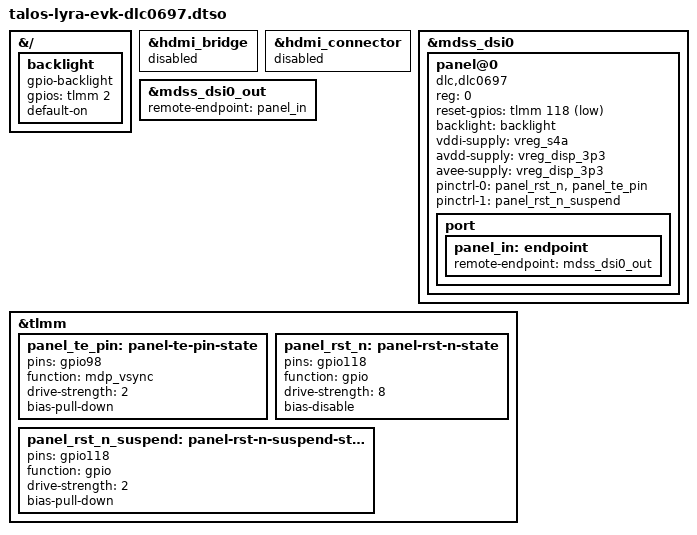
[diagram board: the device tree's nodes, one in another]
// SPDX-License-Identifier: BSD-3-Clause
/*
 * Copyright (c) Qualcomm Technologies, Inc. and/or its subsidiaries.
 */
/dts-v1/;
/plugin/;

#include <dt-bindings/gpio/gpio.h>

&{/} {
	backlight: backlight {
		compatible = "gpio-backlight";
		gpios = <&tlmm 2 GPIO_ACTIVE_HIGH>;
		default-on;
	};
};

&hdmi_bridge {
	status = "disabled";
};

&hdmi_connector {
	status = "disabled";
};

&mdss_dsi0 {
	#address-cells = <1>;
	#size-cells = <0>;

	panel@0 {
		compatible = "dlc,dlc0697", "ilitek,ili7807s";
		reg = <0>;

		reset-gpios = <&tlmm 118 GPIO_ACTIVE_LOW>;
		backlight = <&backlight>;

		vddi-supply = <&vreg_s4a>;
		avdd-supply = <&vreg_disp_3p3>;
		avee-supply = <&vreg_disp_3p3>;

		pinctrl-0 = <&panel_rst_n &panel_te_pin>;
		pinctrl-1 = <&panel_rst_n_suspend>;
		pinctrl-names = "default", "sleep";

		port {
			panel_in: endpoint {
				remote-endpoint = <&mdss_dsi0_out>;
			};
		};
	};
};

&mdss_dsi0_out {
	remote-endpoint = <&panel_in>;
};

&tlmm {
	panel_te_pin: panel-te-pin-state {
		pins = "gpio98";
		function = "mdp_vsync";
		drive-strength = <2>;
		bias-pull-down;
	};

	panel_rst_n: panel-rst-n-state {
		pins = "gpio118";
		function = "gpio";
		drive-strength = <8>;
		bias-disable;
	};

	panel_rst_n_suspend: panel-rst-n-suspend-state {
		pins = "gpio118";
		function = "gpio";
		drive-strength = <2>;
		bias-pull-down;
	};
};
